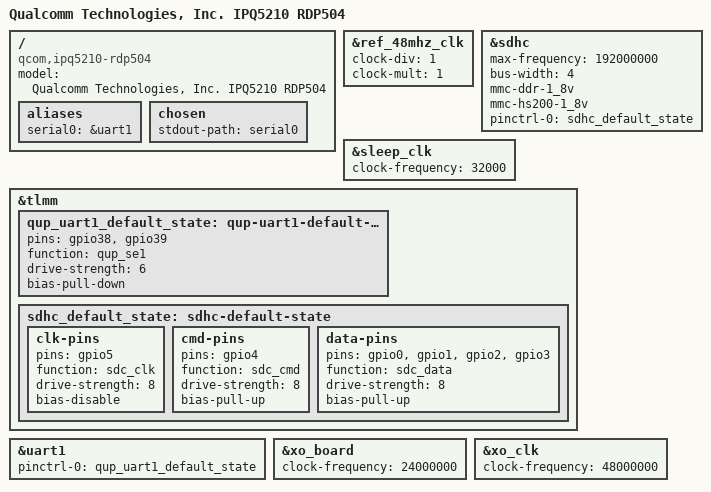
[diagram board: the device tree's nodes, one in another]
// SPDX-License-Identifier: BSD-3-Clause
/*
 * Copyright (c) Qualcomm Technologies, Inc. and/or its subsidiaries.
 */

/dts-v1/;

#include "ipq5210.dtsi"

/ {
	model = "Qualcomm Technologies, Inc. IPQ5210 RDP504";
	compatible = "qcom,ipq5210-rdp504", "qcom,ipq5210";

	aliases {
		serial0 = &uart1;
	};

	chosen {
		stdout-path = "serial0";
	};
};

/*
 * The bootstrap pins for the board select the XO clock frequency that
 * supports 48 MHz, 96 MHz or 192 MHz. This setting automatically
 * enables the right dividers, to ensure the reference clock output
 * from WiFi to the CMN PLL is 48 MHz.
 */
&ref_48mhz_clk {
	clock-div = <1>;
	clock-mult = <1>;
};

&sdhc {
	max-frequency = <192000000>;
	bus-width = <4>;
	mmc-ddr-1_8v;
	mmc-hs200-1_8v;
	pinctrl-0 = <&sdhc_default_state>;
	pinctrl-names = "default";

	status = "okay";
};

&sleep_clk {
	clock-frequency = <32000>;
};

&tlmm {
	qup_uart1_default_state: qup-uart1-default-state {
		pins = "gpio38", "gpio39";
		function = "qup_se1";
		drive-strength = <6>;
		bias-pull-down;
	};

	sdhc_default_state: sdhc-default-state {
		clk-pins {
			pins = "gpio5";
			function = "sdc_clk";
			drive-strength = <8>;
			bias-disable;
		};

		cmd-pins {
			pins = "gpio4";
			function = "sdc_cmd";
			drive-strength = <8>;
			bias-pull-up;
		};

		data-pins {
			pins = "gpio0", "gpio1", "gpio2", "gpio3";
			function = "sdc_data";
			drive-strength = <8>;
			bias-pull-up;
		};
	};
};

&uart1 {
	pinctrl-0 = <&qup_uart1_default_state>;
	pinctrl-names = "default";

	status = "okay";
};

&xo_board {
	clock-frequency = <24000000>;
};

&xo_clk {
	clock-frequency = <48000000>;
};
